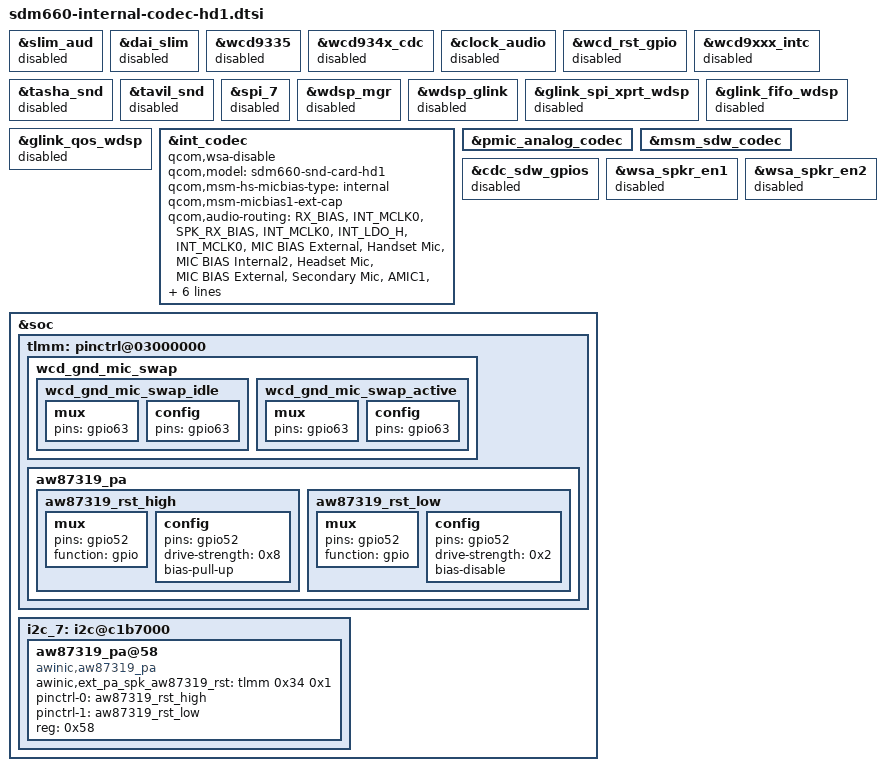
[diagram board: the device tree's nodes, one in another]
/* Copyright (c) 2017, The Linux Foundation. All rights reserved.
 *
 * This program is free software; you can redistribute it and/or modify
 * it under the terms of the GNU General Public License version 2 and
 * only version 2 as published by the Free Software Foundation.
 *
 * This program is distributed in the hope that it will be useful,
 * but WITHOUT ANY WARRANTY; without even the implied warranty of
 * MERCHANTABILITY or FITNESS FOR A PARTICULAR PURPOSE.  See the
 * GNU General Public License for more details.
 */

&slim_aud {
  status = "disabled";
};

&dai_slim {
  status = "disabled";
};

&wcd9335 {
  status = "disabled";
};

&wcd934x_cdc {
  status = "disabled";
};

&clock_audio {
  status = "disabled";
};

&wcd_rst_gpio {
  status = "disabled";
};

&wcd9xxx_intc {
  status = "disabled";
};

&tasha_snd {
  status = "disabled";
};

&tavil_snd {
  status = "disabled";
};

&spi_7 {
  status = "disabled";
};

&wdsp_mgr {
  status = "disabled";
};

&wdsp_glink {
  status = "disabled";
};

&glink_spi_xprt_wdsp {
  status = "disabled";
};

&glink_fifo_wdsp {
  status = "disabled";
};

&glink_qos_wdsp {
  status = "disabled";
};

&int_codec {
  status = "okay";
  qcom,wsa-disable;
  qcom,model = "sdm660-snd-card-hd1";
  /delete-property/ qcom,wsa-max-devs;
  /delete-property/ qcom,wsa-devs;
  /delete-property/ qcom,wsa-aux-dev-prefix;
  /delete-property/ qcom,us-euro-gpios;
   qcom,msm-hs-micbias-type = "internal";
  qcom,msm-micbias1-ext-cap;
  /delete-property/qcom,msm-micbias2-ext-cap;
  /delete-property/qcom,usbc-analog-en2_gpio;
		qcom,audio-routing = "RX_BIAS", "INT_MCLK0", "SPK_RX_BIAS", "INT_MCLK0", "INT_LDO_H",
 "INT_MCLK0", "MIC BIAS External", "Handset Mic", "MIC BIAS Internal2", "Headset Mic", "MIC BIAS External",
 "Secondary Mic", "AMIC1", "MIC BIAS External", "AMIC2", "MIC BIAS Internal2", "AMIC3", "MIC BIAS External",
 "PDM_IN_RX1", "PDM_OUT_RX1", "PDM_IN_RX2", "PDM_OUT_RX2", "PDM_IN_RX3", "PDM_OUT_RX3", "ADC1_IN", "ADC1_OUT", "ADC2_IN", "ADC2_OUT", "ADC3_IN", "ADC3_OUT";

};

&pmic_analog_codec {
  status = "okay";
};



&msm_sdw_codec {
  status = "okay";
};


&cdc_sdw_gpios {
	status = "disabled";
};

&wsa_spkr_en1 {
	status = "disabled";
};

&wsa_spkr_en2 {
	status = "disabled";
};

&soc { 
		
         tlmm: pinctrl@03000000 {
               wcd_gnd_mic_swap {
			wcd_gnd_mic_swap_idle: wcd_gnd_mic_swap_idle {
				mux {
					pins = "gpio63";

				};
				config {
					pins = "gpio63";

				};
			};

			wcd_gnd_mic_swap_active: wcd_gnd_mic_swap_active {
				mux {
					pins = "gpio63";
				};
				config {
					pins = "gpio63";

				};
			};
		};
           };



//	pcm_noirq: qcom,msm-pcm-dsp-noirq {
//		qcom,latency-level = "regular";
//	};

/* awinic smart amp */
	i2c_7: i2c@c1b7000 {

		status = "okay";
		
		aw87319_pa@58    {
			compatible = "awinic,aw87319_pa";
                awinic,ext_pa_spk_aw87319_rst = <&tlmm 0x34 0x1>;
		pinctrl-names = "aw87319_pa_active", "aw87319_pa_off";
		pinctrl-0 = <&aw87319_rst_high>;
		pinctrl-1 = <&aw87319_rst_low>;
			reg = <0x58>;

		};
};
};

&tlmm {
	    
         aw87319_pa {
		aw87319_rst_high: aw87319_rst_high {

					mux {
						pins = "gpio52";
						function = "gpio";
					};

					config {
						pins = "gpio52";
						drive-strength = <0x8>;
						bias-pull-up;
					};
				};

		aw87319_rst_low: aw87319_rst_low {

					mux {
						pins = "gpio52";
						function = "gpio";
					};

					config {
						pins = "gpio52";
						drive-strength = <0x2>;
						bias-disable;
					};
				};
		
    };

};
